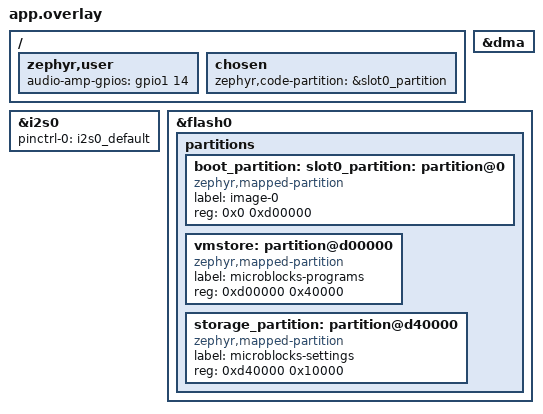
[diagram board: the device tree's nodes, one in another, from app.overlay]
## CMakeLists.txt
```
# SPDX-License-Identifier: MIT
cmake_minimum_required(VERSION 3.28.0)
set(CONF_FILE ../smallvm/prj.conf prj.conf)
find_package(Zephyr REQUIRED HINTS $ENV{ZEPHYR_BASE})
project(waveshare_standalone LANGUAGES C CXX ASM)
if(NOT SMALLVM_SOURCE_DIR OR NOT IDE_SOURCE_DIR)
  message(FATAL_ERROR "Set SMALLVM_SOURCE_DIR and IDE_SOURCE_DIR to verified source snapshots")
endif()
set(repo ${CMAKE_CURRENT_SOURCE_DIR}/../../..)
set(vm_root ${CMAKE_CURRENT_BINARY_DIR}/smallvm)
set(web_root ${CMAKE_CURRENT_BINARY_DIR}/web)
# Optional verified touch-editor cache; no network access during packaging.
set(mobile_args)
if(MOBILE_EDITOR_SOURCE_DIR)
  list(APPEND mobile_args --mobile-source "${MOBILE_EDITOR_SOURCE_DIR}")
endif()
if(CONFIG_I2S_ESP32 AND CONFIG_DMA_ESP32_MAX_DESCRIPTOR_NUM EQUAL 1)
  set(patched_i2s ${CMAKE_CURRENT_BINARY_DIR}/drivers/i2s_esp32.c)
  execute_process(COMMAND ${Python3_EXECUTABLE} ${repo}/tools/prepare_i2s.py
    ${ZEPHYR_BASE}/drivers/i2s/i2s_esp32.c ${patched_i2s}
    COMMAND_ERROR_IS_FATAL ANY)
  get_target_property(i2s_sources drivers__i2s SOURCES)
  list(LENGTH i2s_sources i2s_source_count)
  list(FILTER i2s_sources EXCLUDE REGEX "i2s_esp32\\.c$")
  list(LENGTH i2s_sources i2s_other_count)
  math(EXPR replaced_count "${i2s_source_count} - ${i2s_other_count}")
  if(NOT replaced_count EQUAL 1)
    message(FATAL_ERROR "Expected exactly one pinned ESP32 I2S driver")
  endif()
  set_property(TARGET drivers__i2s PROPERTY SOURCES ${i2s_sources} ${patched_i2s})
endif()
execute_process(COMMAND ${Python3_EXECUTABLE} ${repo}/tools/prepare_smallvm.py
  ${SMALLVM_SOURCE_DIR} ${vm_root} COMMAND_ERROR_IS_FATAL ANY)
execute_process(COMMAND ${Python3_EXECUTABLE} ${repo}/tools/package_ide.py
  ${IDE_SOURCE_DIR} ${web_root} ${mobile_args} COMMAND_ERROR_IS_FATAL ANY)
execute_process(COMMAND ${Python3_EXECUTABLE} ${repo}/tools/generate_device_secrets.py
  ${CMAKE_CURRENT_BINARY_DIR}/private COMMAND_ERROR_IS_FATAL ANY)
target_include_directories(app PRIVATE ${vm_root} ${vm_root}/vm
  ../bringup/src ../smallvm/src src ${CMAKE_CURRENT_BINARY_DIR}/private)
target_compile_definitions(app PRIVATE SMALLVM_ZEPHYR=1 SMALLVM_WEBSOCKET=1)
target_sources(app PRIVATE src/main.cpp src/network.c src/server.c src/transport.c src/program_store.c src/wifi_settings.c
  ../smallvm/src/platform.c ../smallvm/src/arduino_transport.cpp
  ../smallvm/src/generic_primitives.c ../smallvm/src/generic_io.cpp
  ../bringup/src/rlcd_board.c ../bringup/src/rlcd_audio.c ../integration/rlcd_smallvm_primitives.c
  ${vm_root}/vm/interp.c ${vm_root}/vm/runtime.c ${vm_root}/vm/mem.c
  ${vm_root}/vm/persist.c ${vm_root}/vm/dataPrims.c ${vm_root}/vm/varPrims.c
  ${vm_root}/vm/tinyJSON.c ${vm_root}/vm/mbFont.c ${vm_root}/vm/boardHooks.c
  ${web_root}/assets.c ${web_root}/assets.S)
zephyr_linker_sources(SECTIONS sections-rom.ld)
zephyr_linker_section(NAME http_resource_desc_mb_http KVMA RAM_REGION GROUP RODATA_REGION)
```

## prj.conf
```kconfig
# Production runs without a USB console reader. See debug.conf for diagnostics.
CONFIG_CONSOLE=n
CONFIG_UART_CONSOLE=n
CONFIG_PRINTK=n
CONFIG_BOOT_BANNER=n
CONFIG_LOG=n
CONFIG_CHARACTER_FRAMEBUFFER=y
CONFIG_ARDUINO_API_SERIAL_BUFFER_SIZE=64
CONFIG_HEAP_MEM_POOL_SIZE=65536
CONFIG_SYS_HEAP_RUNTIME_STATS=y
CONFIG_NETWORKING=y
CONFIG_WIFI=y
CONFIG_WIFI_NM=y
CONFIG_WIFI_USAGE_MODE_STA_AP=y
CONFIG_NET_CONNECTION_MANAGER=y
CONFIG_NET_CONNECTION_MANAGER_AUTO_IF_DOWN=n
CONFIG_NET_L2_WIFI_MGMT=y
CONFIG_NET_MGMT=y
CONFIG_NET_MGMT_EVENT=y
CONFIG_NET_MGMT_EVENT_INFO=y
CONFIG_NET_MGMT_EVENT_STACK_SIZE=4096
CONFIG_NET_IPV4=y
CONFIG_NET_IPV6=n
CONFIG_NET_DHCPV4=y
CONFIG_NET_DHCPV4_INITIAL_DELAY_MAX=2
CONFIG_NET_DHCPV4_SERVER=y
CONFIG_NET_IF_MAX_IPV4_COUNT=2
CONFIG_NET_TCP=y
CONFIG_NET_UDP=y
CONFIG_NET_SOCKETS=y
# HTTP polls its listener, stop event and up to twelve clients together.
# The default (3) returns ENOMEM with concurrent browser asset requests.
CONFIG_ZVFS_POLL_MAX=16
# Browser connections plus the listen backlog, closing peers, DHCP and VM socket.
CONFIG_NET_MAX_CONTEXTS=32
CONFIG_NET_MAX_CONN=32
CONFIG_NET_PKT_RX_COUNT=16
CONFIG_NET_PKT_TX_COUNT=16
CONFIG_NET_BUF_RX_COUNT=64
CONFIG_NET_BUF_TX_COUNT=64
CONFIG_NET_BUF_DATA_SIZE=256
CONFIG_NET_TCP_TIME_WAIT_DELAY=0
CONFIG_HTTP_SERVER=y
CONFIG_HTTP_SERVER_VERSION_2=n
# Six browser peers, four audit workers, one API probe and VM upgrade headroom.
CONFIG_HTTP_SERVER_MAX_CLIENTS=12
CONFIG_HTTP_SERVER_CLIENT_BUFFER_SIZE=2048
CONFIG_HTTP_SERVER_MAX_URL_LENGTH=192
CONFIG_HTTP_SERVER_MAX_HEADER_LEN=512
# A flash-backed GP package takes about 13 s on the measured Wi-Fi link.
# Other accepted downloads must survive while the HTTP thread sends it.
CONFIG_HTTP_SERVER_CLIENT_INACTIVITY_TIMEOUT=60
CONFIG_HTTP_SERVER_CAPTURE_HEADERS=y
CONFIG_HTTP_SERVER_CAPTURE_HEADER_COUNT=4
CONFIG_HTTP_SERVER_CAPTURE_HEADER_BUFFER_SIZE=512
CONFIG_HTTP_SERVER_WEBSOCKET=y
CONFIG_WEBSOCKET_MAX_CONTEXTS=2
CONFIG_HTTP_SERVER_STACK_SIZE=6144
CONFIG_ESP32_WIFI_STATIC_RX_BUFFER_NUM=6
CONFIG_ESP32_WIFI_DYNAMIC_RX_BUFFER_NUM=12
CONFIG_ESP32_WIFI_STATIC_TX_BUFFER=y
CONFIG_ESP32_WIFI_STATIC_TX_BUFFER_NUM=6
CONFIG_ESP_WIFI_HEAP_SPIRAM=y
CONFIG_ESP32_WIFI_CACHE_TX_BUFFER_NUM=16
CONFIG_ESP32_WIFI_STA_POWER_SAVE_NONE=y
CONFIG_ENTROPY_GENERATOR=y
CONFIG_FLASH=y
CONFIG_FLASH_MAP=y
CONFIG_NVS=y
CONFIG_SETTINGS=y
CONFIG_SETTINGS_NVS=y
CONFIG_REBOOT=y
CONFIG_THREAD_NAME=y
CONFIG_I2S=y
CONFIG_I2S_ESP32_TX_BLOCK_COUNT=4
# Each audio block fits one 4092-byte descriptor. One descriptor selects the
# driver's supported queued/restart path: S3 chained DMA reclaimed blocks early
# in physical tests (200 ms PCM finished in 107 ms with a measured 24 kHz WS).
CONFIG_DMA_ESP32_MAX_DESCRIPTOR_NUM=1
CONFIG_NET_RX_STACK_SIZE=4096
CONFIG_NET_TX_STACK_SIZE=2048
CONFIG_SYSTEM_WORKQUEUE_STACK_SIZE=4096
```

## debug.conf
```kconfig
# Recovery/debug builds only. Keep a serial reader attached during diagnostics.
CONFIG_CONSOLE=y
CONFIG_UART_CONSOLE=y
CONFIG_PRINTK=y
CONFIG_BOOT_BANNER=y
CONFIG_LOG=y
CONFIG_LOG_MODE_IMMEDIATE=y
CONFIG_LOG_DEFAULT_LEVEL=1
CONFIG_NET_LOG=y
CONFIG_NET_DHCPV4_SERVER_LOG_LEVEL_DBG=y
```

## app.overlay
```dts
/* SPDX-License-Identifier: MIT */
#include "../smallvm/app.overlay"
/ {
    zephyr,user {
        audio-amp-gpios = <&gpio1 14 GPIO_ACTIVE_HIGH>;
    };
    chosen {
        zephyr,code-partition = &slot0_partition;
    };
};
&i2s0 {
    status = "okay";
    pinctrl-0 = <&i2s0_default>;
    pinctrl-names = "default";
};
&dma { status = "okay"; };
&flash0 {
    /delete-node/ partitions;
    partitions {
        ranges;
        #address-cells = <1>;
        #size-cells = <1>;
        boot_partition: slot0_partition: partition@0 {
            compatible = "zephyr,mapped-partition";
            label = "image-0";
            reg = <0x0 0xd00000>;
        };
        vmstore: partition@d00000 {
            compatible = "zephyr,mapped-partition";
            label = "microblocks-programs";
            reg = <0xd00000 0x40000>;
        };
        storage_partition: partition@d40000 {
            compatible = "zephyr,mapped-partition";
            label = "microblocks-settings";
            reg = <0xd40000 0x10000>;
        };
    };
};
```

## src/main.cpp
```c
// SPDX-License-Identifier: MPL-2.0
#include <Arduino.h>
#include "vm/interp.h"
#include "vm/persist.h"
extern "C" {
#include "server.h"
}

int main(void)
{
    hardwareInit();
    memInit();
    primsInit();
    printk("MicroBlocks program load: %d\n", mb_store_load());
    restoreScripts();
    startAll();
    int err = mb_network_start();
    printk("MicroBlocks network initialization: %d\n", err);
    if (err == 0) printk("MicroBlocks HTTP initialization: %d\n", mb_server_start());
    for (;;) {
        mb_transport_poll();
        vmSlice(16);
        mb_store_poll();
        delay(1);
    }
}
```

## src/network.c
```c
/* SPDX-License-Identifier: MIT */
#include "server.h"
#include "device_secrets.h"
#include "rlcd_board.h"
#include <zephyr/kernel.h>
#include <zephyr/net/wifi_mgmt.h>
#include <zephyr/net/dhcpv4_server.h>
#include <zephyr/sys/printk.h>
#include <stdio.h>
#include <string.h>

char board_ip[NET_IPV4_ADDR_LEN] = "192.168.4.1";
const char *mb_network_ip(void) { return board_ip; }

static void ap_status_work(struct k_work *work)
{
    ARG_UNUSED(work);
    struct net_if *iface = net_if_get_wifi_sap();
    struct wifi_iface_status status = {0};
    int err = net_mgmt(NET_REQUEST_WIFI_IFACE_STATUS, iface, &status, sizeof(status));
    printk("MicroBlocks AP status: result=%d up=%d carrier=%d dormant=%d state=%d mode=%d ssid_match=%d\n",
        err, net_if_is_up(iface), net_if_is_carrier_ok(iface), net_if_is_dormant(iface),
        status.state, status.iface_mode, !strcmp(status.ssid, MB_DEVICE_SSID));
    if (k_uptime_get() < 90000) k_work_reschedule(k_work_delayable_from_work(work), K_SECONDS(5));
}
K_WORK_DELAYABLE_DEFINE(ap_status, ap_status_work);

int mb_fallback_start(void)
{
    struct net_if *iface = net_if_get_wifi_sap();
    if (!iface) return -ENODEV;
    struct net_in_addr addr, mask;
    net_addr_pton(NET_AF_INET, board_ip, &addr);
    net_addr_pton(NET_AF_INET, "255.255.255.0", &mask);
    if (!net_if_ipv4_addr_add(iface, &addr, NET_ADDR_MANUAL, 0)) return -EIO;
    net_if_ipv4_set_gw(iface, &addr);
    if (!net_if_ipv4_set_netmask_by_addr(iface, &addr, &mask)) return -EIO;
    struct wifi_connect_req_params config = {
        .ssid = (const uint8_t *)MB_DEVICE_SSID,
        .ssid_length = sizeof(MB_DEVICE_SSID) - 1,
        .psk = (const uint8_t *)MB_DEVICE_PSK,
        .psk_length = sizeof(MB_DEVICE_PSK) - 1,
        .channel = 6,
        .band = WIFI_FREQ_BAND_2_4_GHZ,
        .security = WIFI_SECURITY_TYPE_PSK,
    };
    int err = net_mgmt(NET_REQUEST_WIFI_AP_ENABLE, iface, &config, sizeof(config));
    if (err) return err;
    net_if_up(iface);
    printk("MicroBlocks AP interface: %u up=%d\n", net_if_get_by_iface(iface), net_if_is_up(iface));
    addr.s4_addr[3] = 10;
    err = net_dhcpv4_server_start(iface, &addr);
    if (err) return err;
    char screen[384];
    snprintf(screen, sizeof(screen),
             "MicroBlocks\nWireless IDE\n\nWi-Fi network:\n%s\nPassword:\n%s\n\nhttp://%s\n\nProgram in your browser",
             MB_DEVICE_SSID, MB_DEVICE_PSK, board_ip);
    err = rlcd_display_text(screen);
    printk("MicroBlocks LCD status transfer: %d\n", err);
    printk("MicroBlocks fallback AP ready at http://%s\n", board_ip);
    k_work_reschedule(&ap_status, K_SECONDS(3));
    return 0;
}
```

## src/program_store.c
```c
/* SPDX-License-Identifier: MPL-2.0
 * Two alternating snapshots; commit the header only after writing the payload.
 * Called exclusively by the VM thread. Program records persist; live variable
 * values and task stacks do not. */
#include <zephyr/kernel.h>
#include <zephyr/storage/flash_map.h>
#include <zephyr/sys/crc.h>
#include <zephyr/sys/printk.h>
#include <string.h>

extern unsigned char *smallvmCodeData(void);
extern unsigned smallvmCodeSize(void);
#define SLOT_SIZE 0x20000u
#define DATA_OFFSET 4096u
#define MAGIC 0x4d425a31u
struct snapshot_header { uint32_t magic, version, generation, size, crc, reserved[3]; };
static const struct flash_area *area;
static uint32_t generation, saved_crc, observed_crc;
static int active = -1;
static int64_t next_check, changed_at;
static bool baseline;

static bool valid_records(const unsigned char *data, unsigned size)
{
    const uint32_t *words = (const uint32_t *)data;
    if (size < 8 || (words[0] >> 24) != 'S') return false;
    unsigned pos = 1;
    /* v417 uses one cycle-counter word on this platform. */
    while (pos < size / 4) {
        if (words[pos] == UINT32_MAX) return true;
        if ((words[pos] >> 24) != 'R' || pos + 1 >= size / 4) return false;
        uint32_t length = words[pos + 1];
        if (length > size / 4 - pos - 2) return false;
        pos += length + 2;
    }
    return pos == size / 4;
}

int mb_store_load(void)
{
    int err = flash_area_open(FIXED_PARTITION_ID(vmstore), &area);
    if (err) return err;
    if (area->fa_size < 2 * SLOT_SIZE || smallvmCodeSize() > SLOT_SIZE - DATA_OFFSET) return -EFBIG;
    struct snapshot_header h[2];
    bool valid[2] = {false, false};
    for (int i = 0; i < 2; ++i) {
        err = flash_area_read(area, i * SLOT_SIZE, &h[i], sizeof(h[i]));
        valid[i] = !err && h[i].magic == MAGIC && h[i].version == 1 && h[i].size == smallvmCodeSize();
    }
    int first = valid[1] && (!valid[0] || (int32_t)(h[1].generation - h[0].generation) > 0) ? 1 : 0;
    for (int n = 0; n < 2; ++n) {
        int i = first ^ n;
        if (!valid[i]) continue;
        err = flash_area_read(area, i * SLOT_SIZE + DATA_OFFSET, smallvmCodeData(), smallvmCodeSize());
        if (!err && crc32_ieee(smallvmCodeData(), smallvmCodeSize()) == h[i].crc &&
            valid_records(smallvmCodeData(), smallvmCodeSize())) {
            active = i; generation = h[i].generation; saved_crc = observed_crc = h[i].crc;
            baseline = true;
            printk("MicroBlocks program restored: generation %u\n", generation);
            return 0;
        }
    }
    memset(smallvmCodeData(), 0, smallvmCodeSize());
    return -ENOENT;
}

void mb_store_poll(void)
{
    int64_t now = k_uptime_get();
    if (!area || now < next_check) return;
    next_check = now + 1000;
    uint32_t crc = crc32_ieee(smallvmCodeData(), smallvmCodeSize());
    if (!baseline) { saved_crc = observed_crc = crc; baseline = true; return; }
    if (crc != observed_crc) { observed_crc = crc; changed_at = now; return; }
    if (crc == saved_crc || now - changed_at < 2000 || !valid_records(smallvmCodeData(), smallvmCodeSize())) return;
    int slot = active == 0 ? 1 : 0;
    struct snapshot_header h = { .magic = MAGIC, .version = 1, .generation = generation + 1,
        .size = smallvmCodeSize(), .crc = crc };
    int err = flash_area_erase(area, slot * SLOT_SIZE, DATA_OFFSET + smallvmCodeSize());
    if (!err) err = flash_area_write(area, slot * SLOT_SIZE + DATA_OFFSET, smallvmCodeData(), smallvmCodeSize());
    if (!err) err = flash_area_write(area, slot * SLOT_SIZE, &h, sizeof(h));
    if (!err) { active = slot; generation = h.generation; saved_crc = crc; }
    else next_check = now + 10000;
    printk("MicroBlocks program save: %d generation %u\n", err, generation);
}

unsigned mb_store_generation(void) { return generation; }
```

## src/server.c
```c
/* SPDX-License-Identifier: MIT */
#include "server.h"
#include <zephyr/net/http/service.h>
#include <zephyr/kernel.h>
#include <zephyr/sys/sys_heap.h>
#include <zephyr/sys/atomic.h>
#include <string.h>
#include <strings.h>
#include <stdio.h>

static uint16_t port = 80;
HTTP_SERVICE_DEFINE(mb_http, NULL, &port, 12, 12, NULL, NULL, NULL);
HTTP_SERVER_REGISTER_HEADER_CAPTURE(origin_header, "Origin");
static char content_policy[384];

static const struct http_header asset_headers[] = {
    {"Cross-Origin-Opener-Policy", "same-origin"},
    {"Cross-Origin-Embedder-Policy", "require-corp"},
    {"X-Content-Type-Options", "nosniff"},
    {"Cache-Control", "no-cache"},
    {"Referrer-Policy", "no-referrer"},
    {"Content-Security-Policy", content_policy},
};
static const struct http_header gzip_headers[] = {
    {"Content-Encoding", "gzip"},
    {"Cross-Origin-Opener-Policy", "same-origin"},
    {"Cross-Origin-Embedder-Policy", "require-corp"},
    {"X-Content-Type-Options", "nosniff"},
    {"Cache-Control", "no-cache"},
    {"Referrer-Policy", "no-referrer"},
    {"Content-Security-Policy", content_policy},
};

#define ASSET_CHUNK_BYTES 2048u
struct asset_transfer {
    struct http_client_ctx *client;
    const struct mb_asset *asset;
    size_t offset;
};
static struct asset_transfer transfers[CONFIG_HTTP_SERVER_MAX_CLIENTS];
K_MUTEX_DEFINE(asset_transfers_lock);
static atomic_t asset_completed, asset_aborted;

int mb_asset_handler(struct http_client_ctx *client, enum http_transaction_status status,
                     const struct http_request_ctx *request,
                     struct http_response_ctx *response, void *user)
{
    ARG_UNUSED(request);
    const struct mb_asset *asset = user;
    struct asset_transfer *state = NULL, *empty = NULL;
    k_mutex_lock(&asset_transfers_lock, K_FOREVER);
    for (size_t i = 0; i < ARRAY_SIZE(transfers); ++i) {
        if (transfers[i].client == client && transfers[i].asset == asset) state = &transfers[i];
        if (!transfers[i].client && !empty) empty = &transfers[i];
    }
    if (status == HTTP_SERVER_TRANSACTION_COMPLETE || status == HTTP_SERVER_TRANSACTION_ABORTED) {
        if (state) {
            if (status == HTTP_SERVER_TRANSACTION_COMPLETE) atomic_inc(&asset_completed);
            else atomic_inc(&asset_aborted);
            memset(state, 0, sizeof(*state));
        }
        k_mutex_unlock(&asset_transfers_lock);
        return 0;
    }
    if (status != HTTP_SERVER_REQUEST_DATA_FINAL) {
        k_mutex_unlock(&asset_transfers_lock);
        return 0;
    }
    if (!state) {
        state = empty;
        if (!state) { k_mutex_unlock(&asset_transfers_lock); return -ENOMEM; }
        *state = (struct asset_transfer){.client = client, .asset = asset};
    }
    bool first = state->offset == 0;
    size_t count = MIN(asset->size - state->offset, ASSET_CHUNK_BYTES);
    response->body = asset->data + state->offset;
    response->body_len = count;
    if (first) {
        response->headers = asset->gzip ? gzip_headers : asset_headers;
        response->header_count = asset->gzip ? ARRAY_SIZE(gzip_headers) : ARRAY_SIZE(asset_headers);
    }
    state->offset += count;
    response->final_chunk = state->offset == asset->size;
    k_mutex_unlock(&asset_transfers_lock);
    /* A bulk body must not monopolize network servicing. Zephyr requests the
     * next response chunk after sending this one and refreshes its timer. */
    if (!first) k_sleep(K_MSEC(1));
    return 0;
}

static uint8_t ws_buffer[512];
static struct http_resource_detail_websocket vm_ws = {
    .common = {.type=HTTP_RESOURCE_TYPE_WEBSOCKET, .bitmask_of_supported_http_methods=BIT(HTTP_GET)},
    .cb=mb_ws_setup, .data_buffer=ws_buffer, .data_buffer_len=sizeof(ws_buffer),
};
HTTP_RESOURCE_DEFINE(vm_websocket, mb_http, "/ws/vm", &vm_ws);

int mb_server_start(void) {
    snprintf(content_policy, sizeof(content_policy),
        "default-src 'self' data: blob:; connect-src 'self' ws://%s; "
        "script-src 'self' 'unsafe-inline' 'unsafe-eval'; style-src 'self' 'unsafe-inline'; "
        "object-src 'none'; base-uri 'self'; form-action 'self'; frame-ancestors 'self'",
        mb_network_ip());
    return http_server_start();
}

static char wifi_body[128];
static size_t wifi_size;
static bool wifi_allowed;
static int wifi_handler(struct http_client_ctx *client, enum http_transaction_status status,
    const struct http_request_ctx *request, struct http_response_ctx *response, void *user)
{
    ARG_UNUSED(client); ARG_UNUSED(user);
    if (status == HTTP_SERVER_TRANSACTION_COMPLETE || status == HTTP_SERVER_TRANSACTION_ABORTED) {
        memset(wifi_body, 0, sizeof(wifi_body)); wifi_size = 0; wifi_allowed = false; return 0;
    }
    if (request->headers_status != HTTP_HEADER_STATUS_NONE) {
        wifi_allowed = mb_same_origin(request);
    }
    const char *reply = "{\"saved\":false}";
    if (!wifi_allowed) response->status = HTTP_403_FORBIDDEN;
    else if (wifi_size + request->data_len >= sizeof(wifi_body)) response->status = HTTP_413_PAYLOAD_TOO_LARGE;
    else {
        memcpy(wifi_body + wifi_size, request->data, request->data_len); wifi_size += request->data_len;
        if (status != HTTP_SERVER_REQUEST_DATA_FINAL) return 0;
        wifi_body[wifi_size] = 0;
        char *newline = strchr(wifi_body, '\n');
        if (!newline) response->status = HTTP_400_BAD_REQUEST;
        else {
            *newline++ = 0;
            int err = mb_network_save(wifi_body, newline);
            response->status = err ? HTTP_400_BAD_REQUEST : HTTP_200_OK;
            if (!err) reply = "{\"saved\":true,\"restarting\":true}";
        }
    }
    response->body = (const uint8_t *)reply; response->body_len = strlen(reply);
    response->headers = asset_headers; response->header_count = ARRAY_SIZE(asset_headers);
    response->final_chunk = true;
    return 0;
}
static struct http_resource_detail_dynamic wifi_setup = {
    .common={.type=HTTP_RESOURCE_TYPE_DYNAMIC,.bitmask_of_supported_http_methods=BIT(HTTP_POST),.content_type="application/json"},
    .cb=wifi_handler,
};
HTTP_RESOURCE_DEFINE(wifi_api, mb_http, "/api/wifi", &wifi_setup);

static int status_handler(struct http_client_ctx *client, enum http_transaction_status status,
    const struct http_request_ctx *request, struct http_response_ctx *response, void *user)
{
    ARG_UNUSED(client); ARG_UNUSED(request); ARG_UNUSED(user);
    if (status != HTTP_SERVER_REQUEST_DATA_FINAL) return 0;
    static char json[512];
    struct mb_transport_diagnostics ws;
    mb_transport_diagnostics_get(&ws);
    snprintf(json, sizeof(json), "{\"board\":\"Waveshare ESP32-S3-RLCD-4.2\",\"vm\":417,\"ide\":\"2.5.8\",\"saved_generation\":%u,"
        "\"websocket\":{\"sessions\":%u,\"rx_errors\":%u,\"tx_errors\":%u,\"queue_timeouts\":%u,\"last_error\":%d},"
        "\"assets\":{\"chunk_bytes\":%u,\"completed\":%u,\"aborted\":%u}}",
        mb_store_generation(), ws.sessions, ws.rx_errors, ws.tx_errors, ws.queue_timeouts, ws.last_error,
        ASSET_CHUNK_BYTES, (unsigned)atomic_get(&asset_completed), (unsigned)atomic_get(&asset_aborted));
    response->body=(const uint8_t *)json;response->body_len=strlen(json);response->final_chunk=true;
    return 0;
}
static struct http_resource_detail_dynamic status_detail = {
    .common={.type=HTTP_RESOURCE_TYPE_DYNAMIC,.bitmask_of_supported_http_methods=BIT(HTTP_GET),.content_type="application/json"},
    .cb=status_handler,
};
HTTP_RESOURCE_DEFINE(status_api, mb_http, "/api/status", &status_detail);

/* These symbols are supplied by the pinned Zephyr kernel/common libc.
 * The ESP-IDF heap_caps_get_free_size port is a stub, so do not use it.
 * Take the kernel heap lock; malloc_runtime_stats_get locks its own arena.
 */
extern struct k_heap _system_heap;
extern int malloc_runtime_stats_get(struct sys_memory_stats *stats);

static int memory_handler(struct http_client_ctx *client, enum http_transaction_status status,
    const struct http_request_ctx *request, struct http_response_ctx *response, void *user)
{
    ARG_UNUSED(client); ARG_UNUSED(request); ARG_UNUSED(user);
    if (status != HTTP_SERVER_REQUEST_DATA_FINAL) return 0;
    struct sys_memory_stats libc_stats = {0}, kernel_stats = {0};
    int libc_result = malloc_runtime_stats_get(&libc_stats);
    k_spinlock_key_t key = k_spin_lock(&_system_heap.lock);
    int kernel_result = sys_heap_runtime_stats_get(&_system_heap.heap, &kernel_stats);
    k_spin_unlock(&_system_heap.lock, key);
    static char json[512];
    snprintf(json, sizeof(json),
        "{\"libc_malloc\":{\"result\":%d,\"free_bytes\":%zu,\"allocated_bytes\":%zu,\"peak_allocated_bytes\":%zu},"
        "\"kernel_heap\":{\"result\":%d,\"free_bytes\":%zu,\"allocated_bytes\":%zu,\"peak_allocated_bytes\":%zu},"
        "\"uptime_ms\":%u,"
        "\"scope\":\"allocator pools; excludes static arrays, stacks and unassigned physical RAM\"}",
        libc_result, libc_stats.free_bytes, libc_stats.allocated_bytes, libc_stats.max_allocated_bytes,
        kernel_result, kernel_stats.free_bytes, kernel_stats.allocated_bytes, kernel_stats.max_allocated_bytes,
        k_uptime_get_32());
    response->body = (const uint8_t *)json; response->body_len = strlen(json);
    response->headers = asset_headers; response->header_count = ARRAY_SIZE(asset_headers);
    response->final_chunk = true;
    return 0;
}
static struct http_resource_detail_dynamic memory_detail = {
    .common={.type=HTTP_RESOURCE_TYPE_DYNAMIC,.bitmask_of_supported_http_methods=BIT(HTTP_GET),.content_type="application/json"},
    .cb=memory_handler,
};
HTTP_RESOURCE_DEFINE(memory_api, mb_http, "/api/memory", &memory_detail);
```

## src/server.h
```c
/* SPDX-License-Identifier: MIT */
#pragma once
#include <zephyr/net/http/server.h>
struct mb_asset { const unsigned char *data; size_t size; bool gzip; };
int mb_asset_handler(struct http_client_ctx *, enum http_transaction_status,
                     const struct http_request_ctx *, struct http_response_ctx *, void *);
int mb_server_start(void);
int mb_network_start(void);
const char *mb_network_ip(void);
int mb_ws_setup(int, struct http_request_ctx *, void *);
int mb_transport_recv(unsigned char *, int);
int mb_transport_send(unsigned char *, int, int);
void mb_transport_poll(void);
int mb_store_load(void);
void mb_store_poll(void);
unsigned mb_store_generation(void);
int mb_network_save(const char *, const char *);
bool mb_same_origin(const struct http_request_ctx *);
struct mb_transport_diagnostics {
    unsigned sessions, rx_errors, tx_errors, queue_timeouts;
    int last_error;
};
void mb_transport_diagnostics_get(struct mb_transport_diagnostics *out);
```

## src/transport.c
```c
/* SPDX-License-Identifier: MPL-2.0 */
#include "server.h"
#include "generic_io.h"
#include <zephyr/kernel.h>
#include <zephyr/net/websocket.h>
#include <zephyr/sys/ring_buffer.h>
#include <zephyr/sys/atomic.h>
#include <string.h>
#include <strings.h>
#include <stdio.h>

RING_BUF_DECLARE(rx_queue, 8192);
RING_BUF_DECLARE(tx_queue, 8192);
K_MUTEX_DEFINE(queues);
K_SEM_DEFINE(client_ready, 0, 1);
K_SEM_DEFINE(reset_done, 0, 1);
static atomic_t busy;
static atomic_t client_active;
static atomic_t reset_pending;
static atomic_t sessions, rx_errors, tx_errors, queue_timeouts, last_error;
static int client_socket = -1;
extern void smallvmResetTransport(void);

void mb_transport_diagnostics_get(struct mb_transport_diagnostics *out)
{
    *out = (struct mb_transport_diagnostics) {
        .sessions = (unsigned)atomic_get(&sessions),
        .rx_errors = (unsigned)atomic_get(&rx_errors),
        .tx_errors = (unsigned)atomic_get(&tx_errors),
        .queue_timeouts = (unsigned)atomic_get(&queue_timeouts),
        .last_error = (int)atomic_get(&last_error),
    };
}

void mb_transport_poll(void)
{
    if (atomic_cas(&reset_pending, 1, 0)) {
        k_mutex_lock(&queues, K_FOREVER);
        ring_buf_reset(&rx_queue);
        ring_buf_reset(&tx_queue);
        rlcd_io_i2c_cancel();
        smallvmResetTransport();
        k_mutex_unlock(&queues);
        k_sem_give(&reset_done);
    }
}

int mb_transport_recv(unsigned char *data, int count)
{
    k_mutex_lock(&queues, K_FOREVER);
    int n = ring_buf_get(&rx_queue, data, MAX(count, 0));
    k_mutex_unlock(&queues);
    return n;
}

int mb_transport_send(unsigned char *data, int start, int end)
{
    if (!atomic_get(&client_active)) return end - start;
    k_mutex_lock(&queues, K_FOREVER);
    int n = ring_buf_put(&tx_queue, data + start, end - start);
    k_mutex_unlock(&queues);
    return n;
}

static void websocket_worker(void *a, void *b, void *c)
{
    ARG_UNUSED(a); ARG_UNUSED(b); ARG_UNUSED(c);
    uint8_t input[1024], output[1024];
    for (;;) {
        k_sem_take(&client_ready, K_FOREVER);
        int fd = client_socket;
        uint32_t type;
        uint64_t remaining;
        int n;
        k_sem_reset(&reset_done);
        atomic_set(&reset_pending, 1);
        bool valid = k_sem_take(&reset_done, K_SECONDS(1)) == 0;
        if (valid) {
            atomic_set(&client_active, 1);
            int sent = websocket_send_msg(fd, (const uint8_t *)"ready", 5,
                WEBSOCKET_OPCODE_DATA_TEXT, false, true, 1000);
            valid = sent == 5;
            if (!valid) { atomic_inc(&tx_errors); atomic_set(&last_error, sent < 0 ? sent : -EIO); }
            else atomic_inc(&sessions);
        } else {
            atomic_inc(&queue_timeouts);
            atomic_set(&last_error, -ETIMEDOUT);
        }
        size_t message_bytes = 0;
        bool binary = false;
        while (valid) {
            n = websocket_recv_msg(fd, input, sizeof(input), &type, &remaining, 10);
            if (n == -EAGAIN) n = 0;
            else if (n < 0 || (type & WEBSOCKET_FLAG_CLOSE)) {
                if (n < 0 && n != -ENOTCONN) { atomic_inc(&rx_errors); atomic_set(&last_error, n); }
                break;
            }
            if (n > 0) {
                if (type & WEBSOCKET_FLAG_PING) {
                    int sent = websocket_send_msg(fd, input, n, WEBSOCKET_OPCODE_PONG, false, true, 500);
                    if (sent != n) { atomic_inc(&tx_errors); atomic_set(&last_error, sent < 0 ? sent : -EIO); break; }
                    continue;
                }
                if (type & WEBSOCKET_FLAG_BINARY) binary = true;
                if (!binary || (type & WEBSOCKET_FLAG_TEXT) || message_bytes + n + remaining > 8192) {
                    atomic_inc(&rx_errors); atomic_set(&last_error, -EMSGSIZE); break;
                }
                message_bytes += n;
                bool queued = false;
                int64_t deadline = k_uptime_get() + 500;
                do {
                    k_mutex_lock(&queues, K_FOREVER);
                    if (ring_buf_space_get(&rx_queue) >= n) {
                        ring_buf_put(&rx_queue, input, n); queued = true;
                    }
                    k_mutex_unlock(&queues);
                    if (!queued) k_sleep(K_MSEC(1));
                } while (!queued && k_uptime_get() < deadline);
                if (!queued) { atomic_inc(&queue_timeouts); atomic_set(&last_error, -ENOBUFS); break; }
                if ((type & WEBSOCKET_FLAG_FINAL) && remaining == 0) { message_bytes = 0; binary = false; }
            }
            k_mutex_lock(&queues, K_FOREVER);
            int count = ring_buf_get(&tx_queue, output, sizeof(output));
            k_mutex_unlock(&queues);
            if (count) {
                int sent = websocket_send_msg(fd, output, count, WEBSOCKET_OPCODE_DATA_BINARY,
                    false, true, 1000);
                if (sent != count) { atomic_inc(&tx_errors); atomic_set(&last_error, sent < 0 ? sent : -EIO); break; }
            }
        }
        atomic_set(&client_active, 0);
        websocket_unregister(fd);
        client_socket = -1;
        atomic_clear(&busy);
    }
}
K_THREAD_DEFINE(ws_worker, 6144, websocket_worker, NULL, NULL, NULL, 7, 0, 0);

int mb_ws_setup(int fd, struct http_request_ctx *request, void *user)
{
    ARG_UNUSED(user);
    if (!mb_same_origin(request) || !atomic_cas(&busy, 0, 1)) return -EACCES;
    client_socket = fd;
    k_sem_give(&client_ready);
    return 0;
}
```

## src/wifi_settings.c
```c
/* SPDX-License-Identifier: MIT */
#include "server.h"
#include "device_secrets.h"
#include "rlcd_board.h"
#include <zephyr/kernel.h>
#include <zephyr/net/wifi_mgmt.h>
#include <zephyr/net/dhcpv4.h>
#include <zephyr/settings/settings.h>
#include <zephyr/sys/reboot.h>
#include <zephyr/sys/printk.h>
#include <stdio.h>
#include <string.h>
#include <strings.h>

extern char board_ip[NET_IPV4_ADDR_LEN];
extern int mb_fallback_start(void);
static struct { char ssid[33], psk[65]; } credentials;
static struct net_mgmt_event_callback wifi_events;
K_SEM_DEFINE(connected, 0, 1);
static int connect_result;

static int read_settings(const char *name, size_t len, settings_read_cb read, void *arg)
{
    if (strcmp(name, "credentials")) return -ENOENT;
    if (len != sizeof(credentials)) return -EINVAL;
    int n = read(arg, &credentials, sizeof(credentials));
    if (n != sizeof(credentials) || !memchr(credentials.ssid, 0, sizeof(credentials.ssid)) ||
        !memchr(credentials.psk, 0, sizeof(credentials.psk))) {
        memset(&credentials, 0, sizeof(credentials)); return -EINVAL;
    }
    return 0;
}
SETTINGS_STATIC_HANDLER_DEFINE(mb_wifi, "mbwifi", NULL, read_settings, NULL, NULL);

static void reboot_work(struct k_work *work) { ARG_UNUSED(work); sys_reboot(SYS_REBOOT_COLD); }
K_WORK_DELAYABLE_DEFINE(reboot_request, reboot_work);

int mb_network_save(const char *ssid, const char *password)
{
    size_t sn = strlen(ssid), pn = strlen(password);
    if (!sn || sn > 32 || pn > 63 || (pn && pn < 8) || strchr(ssid, '\n') || strchr(password, '\n')) return -EINVAL;
    memset(&credentials, 0, sizeof(credentials));
    memcpy(credentials.ssid, ssid, sn); memcpy(credentials.psk, password, pn);
    int err = settings_save_one("mbwifi/credentials", &credentials, sizeof(credentials));
    if (!err) k_work_reschedule(&reboot_request, K_SECONDS(2));
    return err;
}

bool mb_same_origin(const struct http_request_ctx *request)
{
    char expected[64]; snprintf(expected, sizeof(expected), "http://%s", board_ip);
    for (size_t i = 0; i < request->header_count; ++i)
        if (!strcasecmp(request->headers[i].name, "Origin") &&
            !strcmp(request->headers[i].value, expected)) return true;
    return false;
}

static void wifi_event(struct net_mgmt_event_callback *cb, uint64_t event, struct net_if *iface)
{
    ARG_UNUSED(iface);
    const struct wifi_status *status = cb->info;
    if (event == NET_EVENT_WIFI_CONNECT_RESULT) {
        connect_result = status ? status->status : -EIO;
        k_sem_give(&connected);
    } else if (event == NET_EVENT_WIFI_AP_ENABLE_RESULT) {
        printk("MicroBlocks AP enable result: %d\n", status ? status->status : -EIO);
    } else if (event == NET_EVENT_WIFI_AP_STA_CONNECTED) {
        printk("MicroBlocks AP client connected\n");
    } else if (event == NET_EVENT_WIFI_AP_STA_DISCONNECTED) {
        printk("MicroBlocks AP client disconnected\n");
    }
}

static int station_start(void)
{
    struct net_if *iface = net_if_get_wifi_sta();
    if (!iface) return -ENODEV;
    struct wifi_connect_req_params config = {
        .ssid=(const uint8_t *)credentials.ssid, .ssid_length=strlen(credentials.ssid),
        .psk=(const uint8_t *)credentials.psk, .psk_length=strlen(credentials.psk),
        .security=credentials.psk[0] ? WIFI_SECURITY_TYPE_PSK : WIFI_SECURITY_TYPE_NONE,
        .band=WIFI_FREQ_BAND_2_4_GHZ, .channel=WIFI_CHANNEL_ANY, .timeout=20,
    };
    k_sem_reset(&connected); net_if_up(iface);
    int err = net_mgmt(NET_REQUEST_WIFI_CONNECT, iface, &config, sizeof(config));
    if (err) return err;
    if (k_sem_take(&connected, K_SECONDS(22))) return -ETIMEDOUT;
    if (connect_result) return -ECONNREFUSED;
    net_dhcpv4_start(iface);
    for (int i = 0; i < 100; ++i) {
        struct net_in_addr *address = net_if_ipv4_get_global_addr(iface, NET_ADDR_PREFERRED);
        if (address && address->s_addr) {
            net_addr_ntop(NET_AF_INET, address, board_ip, NET_IPV4_ADDR_LEN);
            char screen[320];
            snprintf(screen, sizeof(screen), "MicroBlocks\nWireless IDE\n\nConnected to Wi-Fi\n\nhttp://%s\n\nKEY at boot: recovery AP", board_ip);
            printk("MicroBlocks LCD status transfer: %d\n", rlcd_display_text(screen));
            printk("MicroBlocks Wi-Fi ready at http://%s\n", board_ip);
            return 0;
        }
        k_sleep(K_MSEC(200));
    }
    net_dhcpv4_stop(iface);
    net_mgmt(NET_REQUEST_WIFI_DISCONNECT, iface, NULL, 0);
    return -ETIMEDOUT;
}

int mb_network_start(void)
{
    int err = settings_subsys_init();
    if (err) return err;
    settings_load_subtree("mbwifi");
    net_mgmt_init_event_callback(&wifi_events, wifi_event,
        NET_EVENT_WIFI_CONNECT_RESULT | NET_EVENT_WIFI_AP_ENABLE_RESULT |
        NET_EVENT_WIFI_AP_STA_CONNECTED | NET_EVENT_WIFI_AP_STA_DISCONNECTED);
    net_mgmt_add_event_callback(&wifi_events);
    /* KEY held during startup selects recovery AP without deleting credentials. */
    if (credentials.ssid[0] && !rlcd_button_pressed(1)) {
        err = station_start();
        printk("MicroBlocks saved network connection result: %d\n", err);
        if (!err) return 0;
    }
    return mb_fallback_start();
}
```
